# CY8C5568AXI_060 register map
File version: 0.1
CY8C55
Registers are 8-bit, read-write, no defined reset value unless marked. A register's access mark holds for its fields unless they carry their own. Offsets are from the block's base; lines under a group give offsets from that group; [hi:lo] are bit positions; {n}, {i} and the like mark numbered series; 'fields as' and 'values as' point back to an identical list; <NAME> marks a mode.

## Memory map
0x00000000 EZI2C

## EZI2C
Base 0x00000000
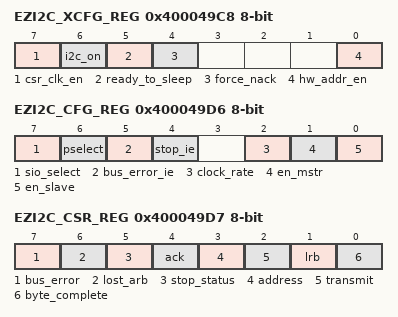
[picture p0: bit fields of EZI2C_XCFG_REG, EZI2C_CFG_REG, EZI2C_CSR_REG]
0x400049C8 EZI2C_XCFG_REG — Extended Configuration Register: I2C_XCFG
  [7] csr_clk_en, [6] i2c_on, [5] ready_to_sleep ro, [4] force_nack, [0] hw_addr_en
0x400049CA EZI2C_ADDR_REG — Slave Adddress Register: I2C_ADR
  [6:0] slave_address — This register holds the slave's 7-bit address.
0x400049D6 EZI2C_CFG_REG — Configuration Register: I2C_CFG
  [7] sio_select, [6] pselect, [5] bus_error_ie, [4] stop_ie, [2] clock_rate, [1] en_mstr, [0] en_slave
0x400049D7 EZI2C_CSR_REG — Control and Status Register: I2C_CSR
  [7] bus_error, [6] lost_arb, [5] stop_status, [4] ack, [3] address, [2] transmit, [1] lrb, [0] byte_complete
0x400049D8 EZI2C_DATA_REG — Data Register: I2C_D
  [7:0] data — This register provides read/write access to the Shift register.
